# test register map
Vendor: Test Ltd.; Series: TestSeries; File version: 1.1
Test svd file
CPU: CM3 r1p2, little endian, MPU, FPU, double-precision FPU, I-cache, D-cache, 4 interrupt priority bits, 9 interrupts
Address unit: 32 bits
Registers are 32-bit, read-write, reset 0x0 unless marked. A register's access mark holds for its fields unless they carry their own. Offsets are from the block's base; lines under a group give offsets from that group; [hi:lo] are bit positions; {n}, {i} and the like mark numbered series; 'fields as' and 'values as' point back to an identical list; <NAME> marks a mode.

## Memory map
0x40002000 TestPeripheral1 size 0x400 — Test peripheral number 1
0x40004000 TestPeripheral1_Derived size 0x400
{0x40008000+0x100*n} TestPeripheral2_[{n}] (n=0..3) size 0x400 — Test peripheral number 2

## Interrupts
1 TEST0 (TestPeripheral1) — Test interrupt 0
2 TEST1 (TestPeripheral1) — Test interrupt 1
4 TEST4 (TestPeripheral2_[{n}]) — Test interrupt 4

## TestPeripheral1 — Test peripheral number 1
Base 0x40002000; register names take the prefix prefix; register names take the suffix suffix
Same registers: TestPeripheral1_Derived 0x40004000
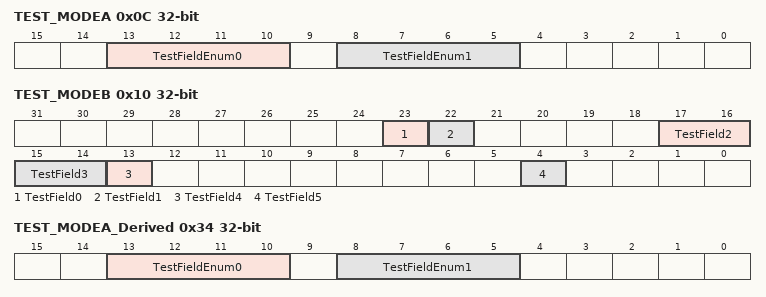
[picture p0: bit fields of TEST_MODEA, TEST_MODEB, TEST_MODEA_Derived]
0x0C TEST_MODEA read-clears — Test register MODEA
  [13:10] TestFieldEnum0 — Test field enumerated value 0
    0=Disable device; 1=Enable device
  [8:5] TestFieldEnum1 — Test field enumerated value 1
    0=Disable device; 1=Enable device
0x10 TEST_MODEB read-clears — Test register MODEB
  [23] TestField0 write-as-read, [22] TestField1, [17:16] TestField2, [15:14] TestField3, [13] TestField4, [4] TestField5
0x34 TEST_MODEA_Derived read-clears — Test register MODEA derived
  fields as TEST_MODEA

## TestPeripheral2_[{n}] — Test peripheral number 2
Base 0x40008000; register names take the prefix prefix; register names take the suffix suffix; array of 4, step 0x100
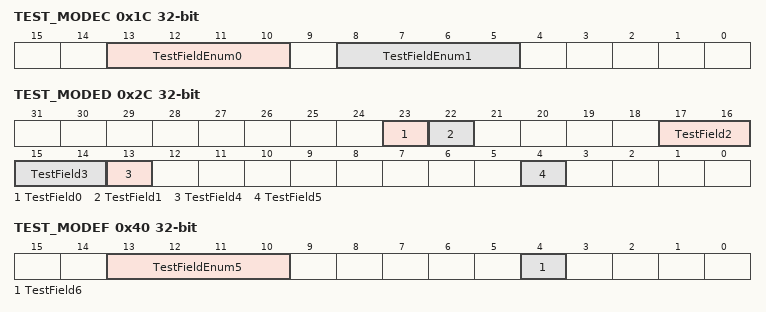
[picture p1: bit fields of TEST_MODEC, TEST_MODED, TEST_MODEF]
0x1C TEST_MODEC read-clears — Test register MODEC
  [13:10] TestFieldEnum0 — Test field enumerated value 0
    0=Disable device; 1=Enable device
  [8:5] TestFieldEnum1 — Test field enumerated value 1
    0=Disable device; 1=Enable device
0x2C TEST_MODED read-clears — Test register MODED
  [23] TestField0 write-as-read, [22] TestField1, [17:16] TestField2, [15:14] TestField3, [13] TestField4, [4] TestField5
0x40 TEST_MODEF read-clears — Test register MODEF
  [13:10] TestFieldEnum5
    0=Disable device; 1=Enable device
  [4] TestField6

## Licence text in the file
MIT License
